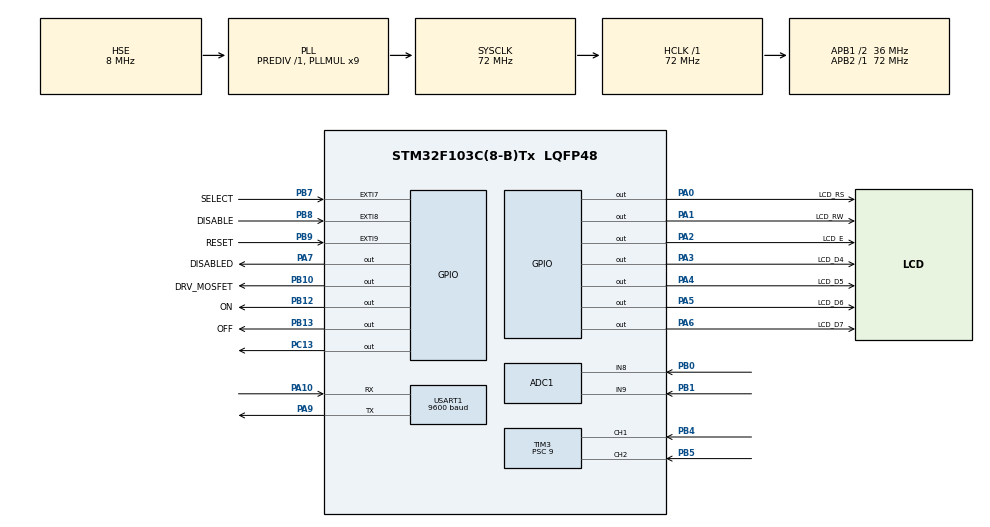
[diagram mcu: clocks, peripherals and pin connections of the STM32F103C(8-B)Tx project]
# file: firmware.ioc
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Mcu.Family=STM32F1
NVIC.ADC1_2_IRQn=true\:0\:0\:false\:false\:true\:true\:true
PB10.GPIO_PuPd=GPIO_PULLDOWN
ADC1.ContinuousConvMode=ENABLE
USART1.BaudRate=9600
TIM3.EncoderMode=TIM_ENCODERMODE_TI12
PA6.GPIO_Label=LCD_D7
PB13.GPIO_Label=OFF
PB13.Signal=GPIO_Output
RCC.SYSCLKSource=RCC_SYSCLKSOURCE_PLLCLK
ProjectManager.StackSize=0x400
PD1-OSC_OUT.Signal=RCC_OSC_OUT
PB8.GPIO_ModeDefaultEXTI=GPIO_MODE_IT_RISING
RCC.HCLKFreq_Value=72000000
RCC.APB2TimFreq_Value=72000000
TIM3.Period=999
Dma.ADC1.0.Direction=DMA_PERIPH_TO_MEMORY
ADC1.Channel-2\#ChannelRegularConversion=ADC_CHANNEL_9
Dma.ADC1.0.MemDataAlignment=DMA_MDATAALIGN_HALFWORD
RCC.AHBFreq_Value=72000000
RCC.PLLMUL=RCC_PLL_MUL9
PB12.GPIO_Label=ON
ADC1.Rank-2\#ChannelRegularConversion=2
TIM3.Prescaler=9
Dma.ADC1.0.PeriphInc=DMA_PINC_DISABLE
NVIC.TIM2_IRQn=true\:0\:0\:false\:false\:true\:true\:true
SH.ADCx_IN8.0=ADC1_IN8,IN8
PB7.Signal=GPXTI7
SH.S_TIM3_CH1.0=TIM3_CH1,Encoder_Interface
PB7.GPIO_Label=SELECT
PB9.Signal=GPXTI9
Mcu.Package=LQFP48
TIM2.Prescaler=7200
PB1.Signal=ADCx_IN9
PA6.Signal=GPIO_Output
PA2.GPIO_Label=LCD_E
PB9.GPIO_PuPd=GPIO_PULLUP
PA10.Signal=USART1_RX
SH.ADCx_IN9.0=ADC1_IN9,IN9
RCC.APB1TimFreq_Value=72000000
Dma.Request0=ADC1
PA4.GPIO_Label=LCD_D5
PB4.Signal=S_TIM3_CH1
PA3.Signal=GPIO_Output
PB7.GPIO_PuPd=GPIO_PULLUP
RCC.PLLSourceVirtual=RCC_PLLSOURCE_HSE
Dma.ADC1.0.Instance=DMA1_Channel1
PD1-OSC_OUT.Mode=HSE-External-Oscillator
PB9.GPIO_Label=RESET
PA10.Mode=Asynchronous
PB8.GPIO_PuPd=GPIO_PULLUP
ADC1.DiscontinuousConvMode=DISABLE
PC13-TAMPER-RTC.Signal=GPIO_Output
PD0-OSC_IN.Signal=RCC_OSC_IN
RCC.APB1CLKDivider=RCC_HCLK_DIV2
VP_SYS_VS_ND.Mode=No_Debug
ADC1.SamplingTime-2\#ChannelRegularConversion=ADC_SAMPLETIME_1CYCLE_5
PA0-WKUP.GPIO_Label=LCD_RS
PA0-WKUP.Signal=GPIO_Output
RCC.ADCPresc=RCC_ADCPCLK2_DIV6
PB8.GPIO_Label=DISABLE
Dma.ADC1.0.PeriphDataAlignment=DMA_PDATAALIGN_HALFWORD
PA9.Mode=Asynchronous
ProjectManager.TargetToolchain=Makefile
TIM3.IC2Filter=10
PB10.GPIO_Label=DRV_MOSFET
Dma.ADC1.0.Mode=DMA_NORMAL
Dma.ADC1.0.Priority=DMA_PRIORITY_LOW
PA9.Signal=USART1_TX
ADC1.Channel-1\#ChannelRegularConversion=ADC_CHANNEL_8
PB4.GPIO_PuPd=GPIO_PULLUP
RCC.USBFreq_Value=72000000
PA1.Signal=GPIO_Output
PD0-OSC_IN.Mode=HSE-External-Oscillator
PB10.Signal=GPIO_Output
PA5.Signal=GPIO_Output
SH.S_TIM3_CH2.0=TIM3_CH2,Encoder_Interface
TIM3.IC1Filter=10
board=custom
RCC.APB2Freq_Value=72000000
VP_TIM2_VS_ClockSourceINT.Mode=Internal
PA1.GPIO_Label=LCD_RW
TIM2.Period=10
ADC1.NbrOfConversion=2
Mcu.Name=STM32F103C(8-B)Tx
PA2.Signal=GPIO_Output
ADC1.ExternalTrigConv=ADC_SOFTWARE_START
PA4.Signal=GPIO_Output
ADC1.SamplingTime-1\#ChannelRegularConversion=ADC_SAMPLETIME_1CYCLE_5
RCC.SYSCLKFreq_VALUE=72000000
PB5.Signal=S_TIM3_CH2
PA7.GPIO_Label=DISABLED
ADC1.master=1
PA5.GPIO_Label=LCD_D6
PB5.GPIO_PuPd=GPIO_PULLUP
USART1.VirtualMode=VM_ASYNC
ADC1.Rank-1\#ChannelRegularConversion=1
NVIC.EXTI9_5_IRQn=true\:0\:0\:false\:false\:true\:true\:true
Dma.ADC1.0.MemInc=DMA_MINC_ENABLE
ProjectManager.HeapSize=0x200
NVIC.PriorityGroup=NVIC_PRIORITYGROUP_4
ADC1.NbrOfConversionFlag=1
PB8.Signal=GPXTI8
NVIC.DMA1_Channel1_IRQn=true\:0\:0\:false\:false\:true\:false\:true
RCC.APB1Freq_Value=36000000
PB0.Signal=ADCx_IN8
PB12.Signal=GPIO_Output
PA3.GPIO_Label=LCD_D4
PA7.Signal=GPIO_Output

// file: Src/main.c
/* USER CODE BEGIN Header */
/**
  ******************************************************************************
  * @file           : main.c
  * @brief          : Main program body
  ******************************************************************************
  * @attention
  *
  * <h2><center>&copy; Copyright (c) 2020 STMicroelectronics.
  * All rights reserved.</center></h2>
  *
  * This software component is licensed by ST under BSD 3-Clause license,
  * the "License"; You may not use this file except in compliance with the
  * License. You may obtain a copy of the License at:
  *                        opensource.org/licenses/BSD-3-Clause
  *
  ******************************************************************************
  */
/* USER CODE END Header */
#include "main.h"

/* USER CODE BEGIN Includes */

#include "logic.h"

/* USER CODE END Includes */

ADC_HandleTypeDef hadc1;
DMA_HandleTypeDef hdma_adc1;

TIM_HandleTypeDef htim2;
TIM_HandleTypeDef htim3;

UART_HandleTypeDef huart1;

void SystemClock_Config(void);
static void MX_GPIO_Init(void);
static void MX_DMA_Init(void);
static void MX_ADC1_Init(void);
static void MX_USART1_UART_Init(void);
static void MX_TIM3_Init(void);
static void MX_TIM2_Init(void);

int main(void)
{

  /* MCU Configuration--------------------------------------------------------*/

  /* Reset of all peripherals, Initializes the Flash interface and the Systick. */
  HAL_Init();

  /* Configure the system clock */
  SystemClock_Config();

  /* Initialize all configured peripherals */
  MX_GPIO_Init();
  MX_DMA_Init();
  MX_ADC1_Init();
  MX_USART1_UART_Init();
  MX_TIM3_Init();
  MX_TIM2_Init();
  /* USER CODE BEGIN 2 */
  logic_init();
  /* USER CODE END 2 */

  /* Infinite loop */
  /* USER CODE BEGIN WHILE */
  while (1)
  {
    logic_update();
    /* USER CODE END WHILE */

  }
}

void SystemClock_Config(void)
{
  RCC_OscInitTypeDef RCC_OscInitStruct = {0};
  RCC_ClkInitTypeDef RCC_ClkInitStruct = {0};
  RCC_PeriphCLKInitTypeDef PeriphClkInit = {0};

  /** Initializes the RCC Oscillators according to the specified parameters
  * in the RCC_OscInitTypeDef structure.
  */
  RCC_OscInitStruct.OscillatorType = RCC_OSCILLATORTYPE_HSE;
  RCC_OscInitStruct.HSEState = RCC_HSE_ON;
  RCC_OscInitStruct.HSEPredivValue = RCC_HSE_PREDIV_DIV1;
  RCC_OscInitStruct.HSIState = RCC_HSI_ON;
  RCC_OscInitStruct.PLL.PLLState = RCC_PLL_ON;
  RCC_OscInitStruct.PLL.PLLSource = RCC_PLLSOURCE_HSE;
  RCC_OscInitStruct.PLL.PLLMUL = RCC_PLL_MUL9;
  if (HAL_RCC_OscConfig(&RCC_OscInitStruct) != HAL_OK)
  {
    Error_Handler();
  }
  /** Initializes the CPU, AHB and APB buses clocks
  */
  RCC_ClkInitStruct.ClockType = RCC_CLOCKTYPE_HCLK|RCC_CLOCKTYPE_SYSCLK
                              |RCC_CLOCKTYPE_PCLK1|RCC_CLOCKTYPE_PCLK2;
  RCC_ClkInitStruct.SYSCLKSource = RCC_SYSCLKSOURCE_PLLCLK;
  RCC_ClkInitStruct.AHBCLKDivider = RCC_SYSCLK_DIV1;
  RCC_ClkInitStruct.APB1CLKDivider = RCC_HCLK_DIV2;
  RCC_ClkInitStruct.APB2CLKDivider = RCC_HCLK_DIV1;

  if (HAL_RCC_ClockConfig(&RCC_ClkInitStruct, FLASH_LATENCY_2) != HAL_OK)
  {
    Error_Handler();
  }
  PeriphClkInit.PeriphClockSelection = RCC_PERIPHCLK_ADC;
  PeriphClkInit.AdcClockSelection = RCC_ADCPCLK2_DIV6;
  if (HAL_RCCEx_PeriphCLKConfig(&PeriphClkInit) != HAL_OK)
  {
    Error_Handler();
  }
}

static void MX_ADC1_Init(void)
{

  ADC_ChannelConfTypeDef sConfig = {0};

  /** Common config
  */
  hadc1.Instance = ADC1;
  hadc1.Init.ScanConvMode = ADC_SCAN_ENABLE;
  hadc1.Init.ContinuousConvMode = ENABLE;
  hadc1.Init.DiscontinuousConvMode = DISABLE;
  hadc1.Init.ExternalTrigConv = ADC_SOFTWARE_START;
  hadc1.Init.DataAlign = ADC_DATAALIGN_RIGHT;
  hadc1.Init.NbrOfConversion = 2;
  if (HAL_ADC_Init(&hadc1) != HAL_OK)
  {
    Error_Handler();
  }
  /** Configure Regular Channel
  */
  sConfig.Channel = ADC_CHANNEL_8;
  sConfig.Rank = ADC_REGULAR_RANK_1;
  sConfig.SamplingTime = ADC_SAMPLETIME_1CYCLE_5;
  if (HAL_ADC_ConfigChannel(&hadc1, &sConfig) != HAL_OK)
  {
    Error_Handler();
  }
  /** Configure Regular Channel
  */
  sConfig.Channel = ADC_CHANNEL_9;
  sConfig.Rank = ADC_REGULAR_RANK_2;
  if (HAL_ADC_ConfigChannel(&hadc1, &sConfig) != HAL_OK)
  {
    Error_Handler();
  }

}

static void MX_TIM2_Init(void)
{

  TIM_ClockConfigTypeDef sClockSourceConfig = {0};
  TIM_MasterConfigTypeDef sMasterConfig = {0};

  htim2.Instance = TIM2;
  htim2.Init.Prescaler = 7200;
  htim2.Init.CounterMode = TIM_COUNTERMODE_UP;
  htim2.Init.Period = 10;
  htim2.Init.ClockDivision = TIM_CLOCKDIVISION_DIV1;
  htim2.Init.AutoReloadPreload = TIM_AUTORELOAD_PRELOAD_DISABLE;
  if (HAL_TIM_Base_Init(&htim2) != HAL_OK)
  {
    Error_Handler();
  }
  sClockSourceConfig.ClockSource = TIM_CLOCKSOURCE_INTERNAL;
  if (HAL_TIM_ConfigClockSource(&htim2, &sClockSourceConfig) != HAL_OK)
  {
    Error_Handler();
  }
  sMasterConfig.MasterOutputTrigger = TIM_TRGO_RESET;
  sMasterConfig.MasterSlaveMode = TIM_MASTERSLAVEMODE_DISABLE;
  if (HAL_TIMEx_MasterConfigSynchronization(&htim2, &sMasterConfig) != HAL_OK)
  {
    Error_Handler();
  }

}

static void MX_TIM3_Init(void)
{

  TIM_Encoder_InitTypeDef sConfig = {0};
  TIM_MasterConfigTypeDef sMasterConfig = {0};

  htim3.Instance = TIM3;
  htim3.Init.Prescaler = 9;
  htim3.Init.CounterMode = TIM_COUNTERMODE_UP;
  htim3.Init.Period = 999;
  htim3.Init.ClockDivision = TIM_CLOCKDIVISION_DIV1;
  htim3.Init.AutoReloadPreload = TIM_AUTORELOAD_PRELOAD_DISABLE;
  sConfig.EncoderMode = TIM_ENCODERMODE_TI12;
  sConfig.IC1Polarity = TIM_ICPOLARITY_RISING;
  sConfig.IC1Selection = TIM_ICSELECTION_DIRECTTI;
  sConfig.IC1Prescaler = TIM_ICPSC_DIV1;
  sConfig.IC1Filter = 10;
  sConfig.IC2Polarity = TIM_ICPOLARITY_RISING;
  sConfig.IC2Selection = TIM_ICSELECTION_DIRECTTI;
  sConfig.IC2Prescaler = TIM_ICPSC_DIV1;
  sConfig.IC2Filter = 10;
  if (HAL_TIM_Encoder_Init(&htim3, &sConfig) != HAL_OK)
  {
    Error_Handler();
  }
  sMasterConfig.MasterOutputTrigger = TIM_TRGO_RESET;
  sMasterConfig.MasterSlaveMode = TIM_MASTERSLAVEMODE_DISABLE;
  if (HAL_TIMEx_MasterConfigSynchronization(&htim3, &sMasterConfig) != HAL_OK)
  {
    Error_Handler();
  }

}

static void MX_USART1_UART_Init(void)
{

  huart1.Instance = USART1;
  huart1.Init.BaudRate = 9600;
  huart1.Init.WordLength = UART_WORDLENGTH_8B;
  huart1.Init.StopBits = UART_STOPBITS_1;
  huart1.Init.Parity = UART_PARITY_NONE;
  huart1.Init.Mode = UART_MODE_TX_RX;
  huart1.Init.HwFlowCtl = UART_HWCONTROL_NONE;
  huart1.Init.OverSampling = UART_OVERSAMPLING_16;
  if (HAL_UART_Init(&huart1) != HAL_OK)
  {
    Error_Handler();
  }

}

static void MX_DMA_Init(void)
{

  /* DMA controller clock enable */
  __HAL_RCC_DMA1_CLK_ENABLE();

  /* DMA interrupt init */
  /* DMA1_Channel1_IRQn interrupt configuration */
  HAL_NVIC_SetPriority(DMA1_Channel1_IRQn, 0, 0);
  HAL_NVIC_EnableIRQ(DMA1_Channel1_IRQn);

}

static void MX_GPIO_Init(void)
{
  GPIO_InitTypeDef GPIO_InitStruct = {0};

  /* GPIO Ports Clock Enable */
  __HAL_RCC_GPIOC_CLK_ENABLE();
  __HAL_RCC_GPIOD_CLK_ENABLE();
  __HAL_RCC_GPIOA_CLK_ENABLE();
  __HAL_RCC_GPIOB_CLK_ENABLE();

  /*Configure GPIO pin Output Level */
  HAL_GPIO_WritePin(GPIOC, GPIO_PIN_13, GPIO_PIN_RESET);

  /*Configure GPIO pin Output Level */
  HAL_GPIO_WritePin(GPIOA, LCD_RS_Pin|LCD_RW_Pin|LCD_E_Pin|LCD_D4_Pin
                          |LCD_D5_Pin|LCD_D6_Pin|LCD_D7_Pin|DISABLED_Pin, GPIO_PIN_RESET);

  /*Configure GPIO pin Output Level */
  HAL_GPIO_WritePin(GPIOB, DRV_MOSFET_Pin|ON_Pin|OFF_Pin, GPIO_PIN_RESET);

  /*Configure GPIO pin : PC13 */
  GPIO_InitStruct.Pin = GPIO_PIN_13;
  GPIO_InitStruct.Mode = GPIO_MODE_OUTPUT_PP;
  GPIO_InitStruct.Pull = GPIO_NOPULL;
  GPIO_InitStruct.Speed = GPIO_SPEED_FREQ_LOW;
  HAL_GPIO_Init(GPIOC, &GPIO_InitStruct);

  /*Configure GPIO pins : LCD_RS_Pin LCD_RW_Pin LCD_E_Pin LCD_D4_Pin
                           LCD_D5_Pin LCD_D6_Pin LCD_D7_Pin DISABLED_Pin */
  GPIO_InitStruct.Pin = LCD_RS_Pin|LCD_RW_Pin|LCD_E_Pin|LCD_D4_Pin
                          |LCD_D5_Pin|LCD_D6_Pin|LCD_D7_Pin|DISABLED_Pin;
  GPIO_InitStruct.Mode = GPIO_MODE_OUTPUT_PP;
  GPIO_InitStruct.Pull = GPIO_NOPULL;
  GPIO_InitStruct.Speed = GPIO_SPEED_FREQ_LOW;
  HAL_GPIO_Init(GPIOA, &GPIO_InitStruct);

  /*Configure GPIO pin : DRV_MOSFET_Pin */
  GPIO_InitStruct.Pin = DRV_MOSFET_Pin;
  GPIO_InitStruct.Mode = GPIO_MODE_OUTPUT_PP;
  GPIO_InitStruct.Pull = GPIO_PULLDOWN;
  GPIO_InitStruct.Speed = GPIO_SPEED_FREQ_LOW;
  HAL_GPIO_Init(DRV_MOSFET_GPIO_Port, &GPIO_InitStruct);

  /*Configure GPIO pins : ON_Pin OFF_Pin */
  GPIO_InitStruct.Pin = ON_Pin|OFF_Pin;
  GPIO_InitStruct.Mode = GPIO_MODE_OUTPUT_PP;
  GPIO_InitStruct.Pull = GPIO_NOPULL;
  GPIO_InitStruct.Speed = GPIO_SPEED_FREQ_LOW;
  HAL_GPIO_Init(GPIOB, &GPIO_InitStruct);

  /*Configure GPIO pins : SELECT_Pin DISABLE_Pin RESET_Pin */
  GPIO_InitStruct.Pin = SELECT_Pin|DISABLE_Pin|RESET_Pin;
  GPIO_InitStruct.Mode = GPIO_MODE_IT_RISING;
  GPIO_InitStruct.Pull = GPIO_PULLUP;
  HAL_GPIO_Init(GPIOB, &GPIO_InitStruct);

  /* EXTI interrupt init*/
  HAL_NVIC_SetPriority(EXTI9_5_IRQn, 0, 0);
  HAL_NVIC_EnableIRQ(EXTI9_5_IRQn);

}

void Error_Handler(void)
{
}

/************************ (C) COPYRIGHT STMicroelectronics *****END OF FILE****/
